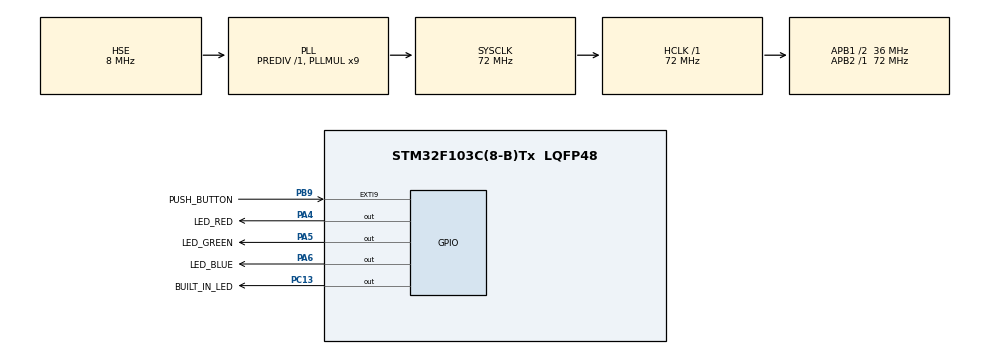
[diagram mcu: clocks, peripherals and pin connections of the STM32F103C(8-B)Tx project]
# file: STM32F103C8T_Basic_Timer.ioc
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Mcu.Family=STM32F1
Mcu.Name=STM32F103C(8-B)Tx
Mcu.Package=LQFP48
NVIC.EXTI9_5_IRQn=true\:0\:0\:false\:false\:true\:true\:true\:true
NVIC.PriorityGroup=NVIC_PRIORITYGROUP_4
NVIC.TIM4_IRQn=true\:0\:0\:false\:false\:true\:true\:true\:true
PA13.Mode=Trace_Asynchronous_SW
PA13.Signal=SYS_JTMS-SWDIO
PA14.Mode=Trace_Asynchronous_SW
PA14.Signal=SYS_JTCK-SWCLK
PA4.GPIO_Label=LED_RED
PA4.GPIO_Speed=GPIO_SPEED_FREQ_HIGH
PA4.Signal=GPIO_Output
PA5.GPIO_Label=LED_GREEN
PA5.GPIO_Speed=GPIO_SPEED_FREQ_HIGH
PA5.Signal=GPIO_Output
PA6.GPIO_Label=LED_BLUE
PA6.GPIO_Speed=GPIO_SPEED_FREQ_HIGH
PA6.Signal=GPIO_Output
PB3.Mode=Trace_Asynchronous_SW
PB3.Signal=SYS_JTDO-TRACESWO
PB9.GPIO_Label=PUSH_BUTTON
PB9.Signal=GPXTI9
PC13-TAMPER-RTC.GPIO_Label=BUILT_IN_LED
PC13-TAMPER-RTC.GPIO_Speed=GPIO_SPEED_FREQ_HIGH
PC13-TAMPER-RTC.Signal=GPIO_Output
PC14-OSC32_IN.Mode=LSE-External-Oscillator
PC14-OSC32_IN.Signal=RCC_OSC32_IN
PC15-OSC32_OUT.Mode=LSE-External-Oscillator
PC15-OSC32_OUT.Signal=RCC_OSC32_OUT
PD0-OSC_IN.Mode=HSE-External-Oscillator
PD0-OSC_IN.Signal=RCC_OSC_IN
PD1-OSC_OUT.Mode=HSE-External-Oscillator
PD1-OSC_OUT.Signal=RCC_OSC_OUT
ProjectManager.HeapSize=0x200
ProjectManager.StackSize=0x400
ProjectManager.TargetToolchain=STM32CubeIDE
RCC.AHBFreq_Value=72000000
RCC.APB1CLKDivider=RCC_HCLK_DIV2
RCC.APB1Freq_Value=36000000
RCC.APB1TimFreq_Value=72000000
RCC.APB2Freq_Value=72000000
RCC.APB2TimFreq_Value=72000000
RCC.HCLKFreq_Value=72000000
RCC.PLLMUL=RCC_PLL_MUL9
RCC.PLLSourceVirtual=RCC_PLLSOURCE_HSE
RCC.SYSCLKFreq_VALUE=72000000
RCC.SYSCLKSource=RCC_SYSCLKSOURCE_PLLCLK
RCC.USBFreq_Value=72000000
TIM4.AutoReloadPreload=TIM_AUTORELOAD_PRELOAD_ENABLE
TIM4.CounterMode=TIM_COUNTERMODE_UP
TIM4.Period=0
TIM4.Prescaler=72 - 1
VP_TIM4_VS_ClockSourceINT.Mode=Internal
board=custom

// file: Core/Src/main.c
/* USER CODE BEGIN Header */
/**
  ******************************************************************************
  * @file           : main.c
  * @brief          : Main program body
  ******************************************************************************
  * @attention
  *
  * Copyright (c) 2026 STMicroelectronics.
  * All rights reserved.
  *
  * This software is licensed under terms that can be found in the LICENSE file
  * in the root directory of this software component.
  * If no LICENSE file comes with this software, it is provided AS-IS.
  *
  ******************************************************************************
  */
/* USER CODE END Header */
#include "main.h"

TIM_HandleTypeDef htim4;

/* USER CODE BEGIN PV */
uint32_t tim4_state = 0;
/* USER CODE END PV */

void SystemClock_Config(void);
static void MX_GPIO_Init(void);
static void MX_TIM4_Init(void);
/* USER CODE BEGIN PFP */
void delay_ms(uint16_t ms);
/* USER CODE END PFP */

int main(void)
{

  /* MCU Configuration--------------------------------------------------------*/

  /* Reset of all peripherals, Initializes the Flash interface and the Systick. */
  HAL_Init();

  /* Configure the system clock */
  SystemClock_Config();

  /* Initialize all configured peripherals */
  MX_GPIO_Init();
  MX_TIM4_Init();
  /* USER CODE BEGIN 2 */
  //HAL_TIM_Base_Start_IT(&htim4);
  /* USER CODE END 2 */

  /* Infinite loop */
  while (1)
  {

    /* USER CODE BEGIN 3 */
	  HAL_GPIO_TogglePin(GPIOA, LED_RED_Pin|LED_GREEN_Pin|LED_BLUE_Pin);
	  delay_ms(1000);
  }
  /* USER CODE END 3 */
}

void SystemClock_Config(void)
{
  RCC_OscInitTypeDef RCC_OscInitStruct = {0};
  RCC_ClkInitTypeDef RCC_ClkInitStruct = {0};

  /** Initializes the RCC Oscillators according to the specified parameters
  * in the RCC_OscInitTypeDef structure.
  */
  RCC_OscInitStruct.OscillatorType = RCC_OSCILLATORTYPE_HSE;
  RCC_OscInitStruct.HSEState = RCC_HSE_ON;
  RCC_OscInitStruct.HSEPredivValue = RCC_HSE_PREDIV_DIV1;
  RCC_OscInitStruct.HSIState = RCC_HSI_ON;
  RCC_OscInitStruct.PLL.PLLState = RCC_PLL_ON;
  RCC_OscInitStruct.PLL.PLLSource = RCC_PLLSOURCE_HSE;
  RCC_OscInitStruct.PLL.PLLMUL = RCC_PLL_MUL9;
  if (HAL_RCC_OscConfig(&RCC_OscInitStruct) != HAL_OK)
  {
    Error_Handler();
  }

  /** Initializes the CPU, AHB and APB buses clocks
  */
  RCC_ClkInitStruct.ClockType = RCC_CLOCKTYPE_HCLK|RCC_CLOCKTYPE_SYSCLK
                              |RCC_CLOCKTYPE_PCLK1|RCC_CLOCKTYPE_PCLK2;
  RCC_ClkInitStruct.SYSCLKSource = RCC_SYSCLKSOURCE_PLLCLK;
  RCC_ClkInitStruct.AHBCLKDivider = RCC_SYSCLK_DIV1;
  RCC_ClkInitStruct.APB1CLKDivider = RCC_HCLK_DIV2;
  RCC_ClkInitStruct.APB2CLKDivider = RCC_HCLK_DIV1;

  if (HAL_RCC_ClockConfig(&RCC_ClkInitStruct, FLASH_LATENCY_2) != HAL_OK)
  {
    Error_Handler();
  }
}

static void MX_TIM4_Init(void)
{

  TIM_ClockConfigTypeDef sClockSourceConfig = {0};
  TIM_MasterConfigTypeDef sMasterConfig = {0};

  htim4.Instance = TIM4;
  htim4.Init.Prescaler = 7200 - 1;
  htim4.Init.CounterMode = TIM_COUNTERMODE_UP;
  htim4.Init.Period = 65536 -1;
  htim4.Init.ClockDivision = TIM_CLOCKDIVISION_DIV1;
  htim4.Init.AutoReloadPreload = TIM_AUTORELOAD_PRELOAD_ENABLE;
  if (HAL_TIM_Base_Init(&htim4) != HAL_OK)
  {
    Error_Handler();
  }
  sClockSourceConfig.ClockSource = TIM_CLOCKSOURCE_INTERNAL;
  if (HAL_TIM_ConfigClockSource(&htim4, &sClockSourceConfig) != HAL_OK)
  {
    Error_Handler();
  }
  sMasterConfig.MasterOutputTrigger = TIM_TRGO_RESET;
  sMasterConfig.MasterSlaveMode = TIM_MASTERSLAVEMODE_DISABLE;
  if (HAL_TIMEx_MasterConfigSynchronization(&htim4, &sMasterConfig) != HAL_OK)
  {
    Error_Handler();
  }

}

static void MX_GPIO_Init(void)
{
  GPIO_InitTypeDef GPIO_InitStruct = {0};

  /* GPIO Ports Clock Enable */
  __HAL_RCC_GPIOC_CLK_ENABLE();
  __HAL_RCC_GPIOD_CLK_ENABLE();
  __HAL_RCC_GPIOA_CLK_ENABLE();
  __HAL_RCC_GPIOB_CLK_ENABLE();

  /*Configure GPIO pin Output Level */
  HAL_GPIO_WritePin(BUILT_IN_LED_GPIO_Port, BUILT_IN_LED_Pin, GPIO_PIN_RESET);

  /*Configure GPIO pin Output Level */
  HAL_GPIO_WritePin(GPIOA, LED_RED_Pin|LED_GREEN_Pin|LED_BLUE_Pin, GPIO_PIN_RESET);

  /*Configure GPIO pin : BUILT_IN_LED_Pin */
  GPIO_InitStruct.Pin = BUILT_IN_LED_Pin;
  GPIO_InitStruct.Mode = GPIO_MODE_OUTPUT_PP;
  GPIO_InitStruct.Pull = GPIO_NOPULL;
  GPIO_InitStruct.Speed = GPIO_SPEED_FREQ_HIGH;
  HAL_GPIO_Init(BUILT_IN_LED_GPIO_Port, &GPIO_InitStruct);

  /*Configure GPIO pins : LED_RED_Pin LED_GREEN_Pin LED_BLUE_Pin */
  GPIO_InitStruct.Pin = LED_RED_Pin|LED_GREEN_Pin|LED_BLUE_Pin;
  GPIO_InitStruct.Mode = GPIO_MODE_OUTPUT_PP;
  GPIO_InitStruct.Pull = GPIO_NOPULL;
  GPIO_InitStruct.Speed = GPIO_SPEED_FREQ_HIGH;
  HAL_GPIO_Init(GPIOA, &GPIO_InitStruct);

  /*Configure GPIO pin : PUSH_BUTTON_Pin */
  GPIO_InitStruct.Pin = PUSH_BUTTON_Pin;
  GPIO_InitStruct.Mode = GPIO_MODE_IT_RISING;
  GPIO_InitStruct.Pull = GPIO_NOPULL;
  HAL_GPIO_Init(PUSH_BUTTON_GPIO_Port, &GPIO_InitStruct);

  /* EXTI interrupt init*/
  HAL_NVIC_SetPriority(EXTI9_5_IRQn, 0, 0);
  HAL_NVIC_EnableIRQ(EXTI9_5_IRQn);

}

/* USER CODE BEGIN 4 */

void HAL_GPIO_EXTI_Callback(uint16_t GPIO_Pin)
{
	/*
  if (GPIO_Pin == PUSH_BUTTON_Pin)
  {
	  if (tim4_state == 0)
	  {
		  HAL_TIM_Base_Start_IT(&htim4);
		  tim4_state = 1;
	  } else
	  {
		  HAL_TIM_Base_Stop_IT(&htim4);
		  tim4_state=0;
	  }

  }*/
}

void HAL_TIM_PeriodElapsedCallback(TIM_HandleTypeDef *htim)
{
  HAL_GPIO_TogglePin(GPIOA,LED_RED_Pin|LED_GREEN_Pin|LED_BLUE_Pin);
}

void delay_ms(uint16_t ms)
{
    // 1. Reset the timer counter to 0
    __HAL_TIM_SET_COUNTER(&htim4, 0);

    // 2. Start the timer in polling mode
    HAL_TIM_Base_Start(&htim4);

    // 3. Wait until the counter reaches the desired value
    while (__HAL_TIM_GET_COUNTER(&htim4) < ms);

    // 4. Stop the timer
    HAL_TIM_Base_Stop(&htim4);
}

/* USER CODE END 4 */

void Error_Handler(void)
{
  __disable_irq();
  while (1)
  {
  }
}
